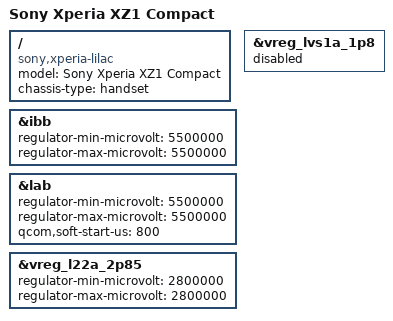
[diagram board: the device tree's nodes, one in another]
// SPDX-License-Identifier: BSD-3-Clause
/*
 * Copyright (c) 2021, AngeloGioacchino Del Regno
 *                     <angelogioacchino.delregno@somainline.org>
 */

/dts-v1/;

#include "msm8998-sony-xperia-yoshino.dtsi"

/ {
	model = "Sony Xperia XZ1 Compact";
	compatible = "sony,xperia-lilac", "qcom,msm8998";
	chassis-type = "handset";
};

&ibb {
	regulator-min-microvolt = <5500000>;
	regulator-max-microvolt = <5500000>;
};

&lab {
	regulator-min-microvolt = <5500000>;
	regulator-max-microvolt = <5500000>;
	qcom,soft-start-us = <800>;
};

&vreg_l22a_2p85 {
	regulator-min-microvolt = <2800000>;
	regulator-max-microvolt = <2800000>;
};

&vreg_lvs1a_1p8 {
	status = "disabled";
};
